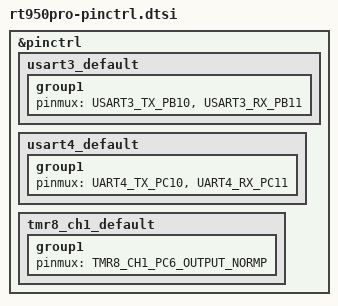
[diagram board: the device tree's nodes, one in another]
/*
 * SPDX-FileCopyrightText: Copyright 2020-2026 OpenRTX Contributors
 *
 * SPDX-License-Identifier: GPL-3.0-or-later
 */

#include <dt-bindings/pinctrl/at32f403av(g)xx-pinctrl.h>

&pinctrl {
	/* GPS module */
	usart3_default: usart3_default {
		group1 {
			pinmux = <USART3_TX_PB10>, <USART3_RX_PB11>;
		};
	};

	/* UART4 on the programming cable connector */
	usart4_default: usart4_default {
		group1 {
			pinmux = <UART4_TX_PC10>, <UART4_RX_PC11>;
		};
	};

	/* LCD backlight PWM */
	tmr8_ch1_default: tmr8_ch1_default {
		group1 {
			pinmux = <TMR8_CH1_PC6_OUTPUT_NORMP>;
		};
	};
};
